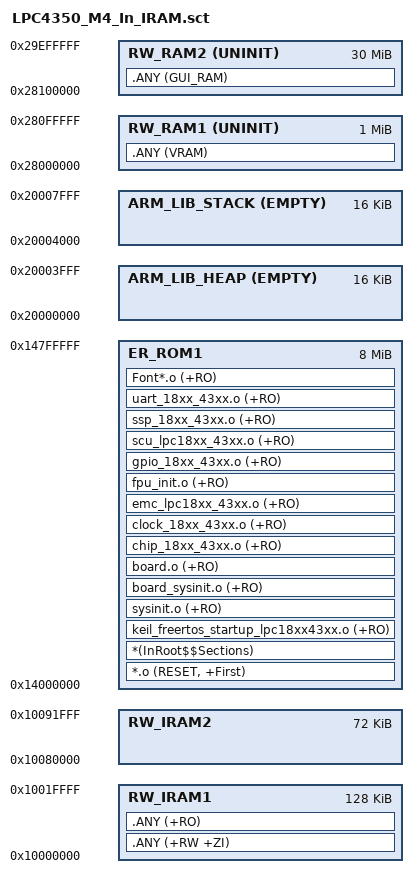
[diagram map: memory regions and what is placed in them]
; *************************************************************
; *** Scatter-Loading Description File generated by uVision ***
; *************************************************************

LR_ROM1 0x14000000 0x00800000  {    ; load region size_region
  ER_ROM1 0x14000000 0x00800000  {  ; load address = execution address
   *.o (RESET, +First)
   *(InRoot$$Sections)
   keil_freertos_startup_lpc18xx43xx.o (+RO)
   sysinit.o (+RO)
   board_sysinit.o (+RO)
   board.o (+RO)
   
   chip_18xx_43xx.o (+RO)
   clock_18xx_43xx.o (+RO)
   emc_lpc18xx_43xx.o (+RO)
   fpu_init.o (+RO)
   gpio_18xx_43xx.o (+RO)
   scu_lpc18xx_43xx.o (+RO)
   ssp_18xx_43xx.o (+RO)
   uart_18xx_43xx.o (+RO)
   Font*.o (+RO)
  }
  
  RW_IRAM1 0x10000000 0x00020000  {
   .ANY (+RW +ZI)
   .ANY (+RO)
  }
  
  RW_IRAM2 0x10080000 0x00012000  {
   
  }
  
  ARM_LIB_HEAP 0x20000000 EMPTY 0x4000 {
  }
  ARM_LIB_STACK 0x20008000 EMPTY -0x4000{
  }
    
  RW_RAM1 0x28000000 UNINIT 0x00100000 {
   .ANY (VRAM)
  }
  
  RW_RAM2 0x28100000 UNINIT 0x01E00000 {
   .ANY (GUI_RAM)
  }
  
}
